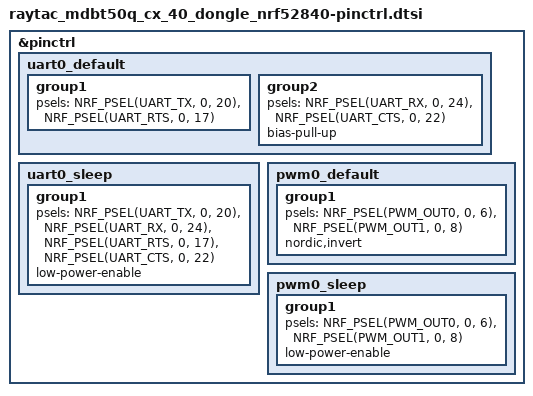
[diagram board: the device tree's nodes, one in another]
/*
 * Copyright (c) 2018-2023 Nordic Semiconductor ASA
 * Copyright (c) 2025 Raytac Corporation.
 * SPDX-License-Identifier: Apache-2.0
 */

&pinctrl {
	uart0_default: uart0_default {
		group1 {
			psels = <NRF_PSEL(UART_TX, 0, 20)>,
				<NRF_PSEL(UART_RTS, 0, 17)>;
		};

		group2 {
			psels = <NRF_PSEL(UART_RX, 0, 24)>,
				<NRF_PSEL(UART_CTS, 0, 22)>;
			bias-pull-up;
		};
	};

	uart0_sleep: uart0_sleep {
		group1 {
			psels = <NRF_PSEL(UART_TX, 0, 20)>,
				<NRF_PSEL(UART_RX, 0, 24)>,
				<NRF_PSEL(UART_RTS, 0, 17)>,
				<NRF_PSEL(UART_CTS, 0, 22)>;
			low-power-enable;
		};
	};

	pwm0_default: pwm0_default {
		group1 {
			psels = <NRF_PSEL(PWM_OUT0, 0, 6)>,
				<NRF_PSEL(PWM_OUT1, 0, 8)>;
			nordic,invert;
		};
	};

	pwm0_sleep: pwm0_sleep {
		group1 {
			psels = <NRF_PSEL(PWM_OUT0, 0, 6)>,
				<NRF_PSEL(PWM_OUT1, 0, 8)>;
			low-power-enable;
		};
	};
};
